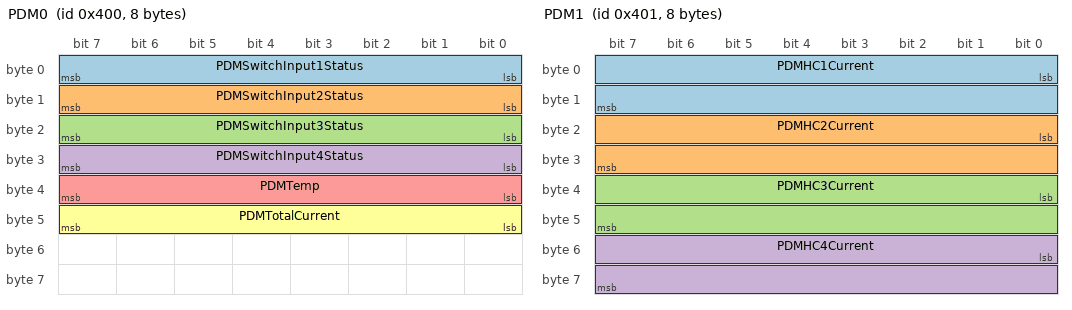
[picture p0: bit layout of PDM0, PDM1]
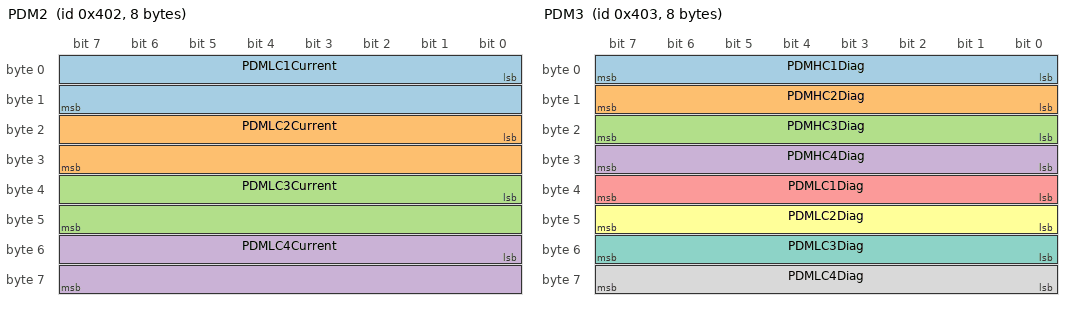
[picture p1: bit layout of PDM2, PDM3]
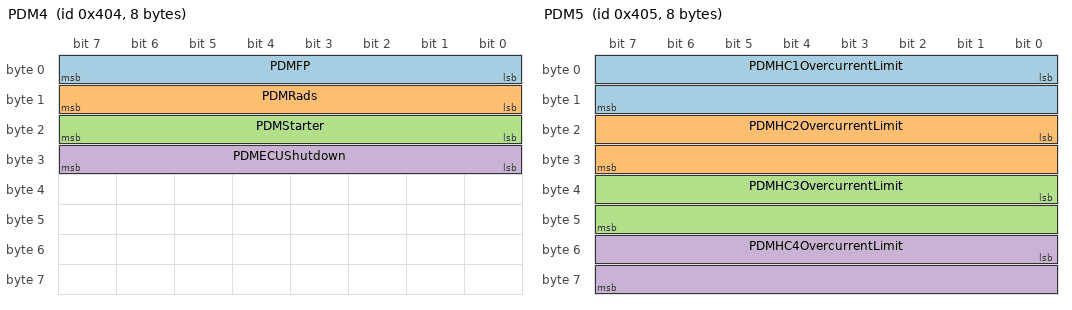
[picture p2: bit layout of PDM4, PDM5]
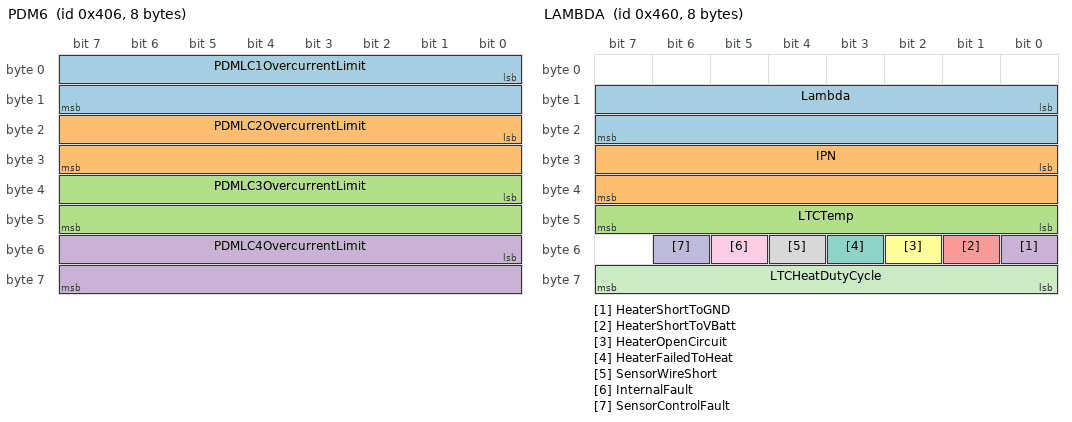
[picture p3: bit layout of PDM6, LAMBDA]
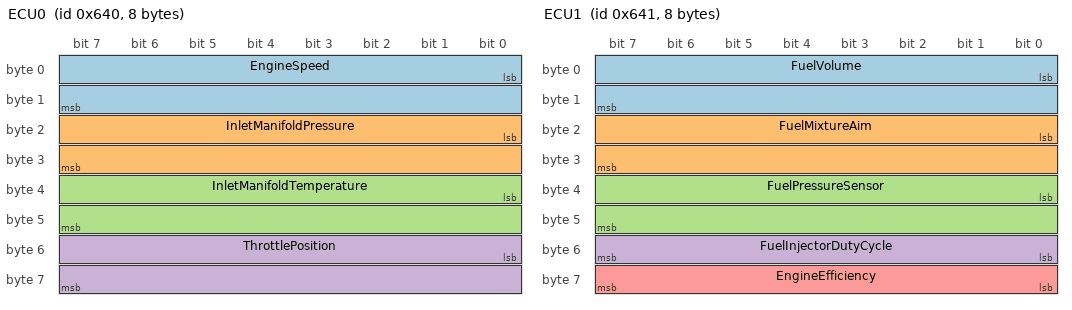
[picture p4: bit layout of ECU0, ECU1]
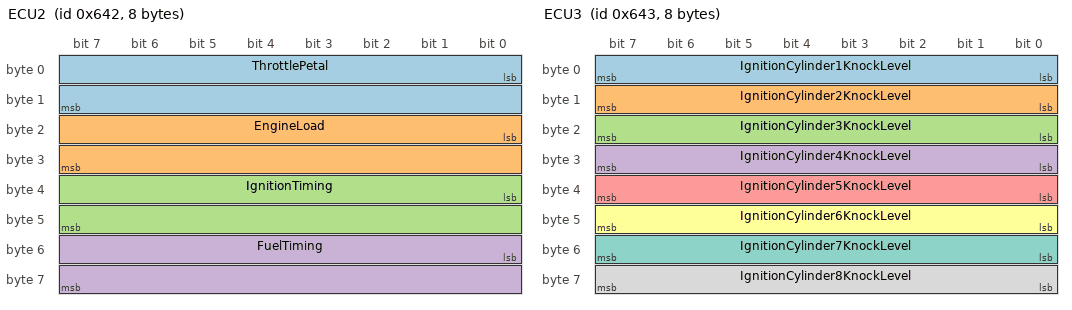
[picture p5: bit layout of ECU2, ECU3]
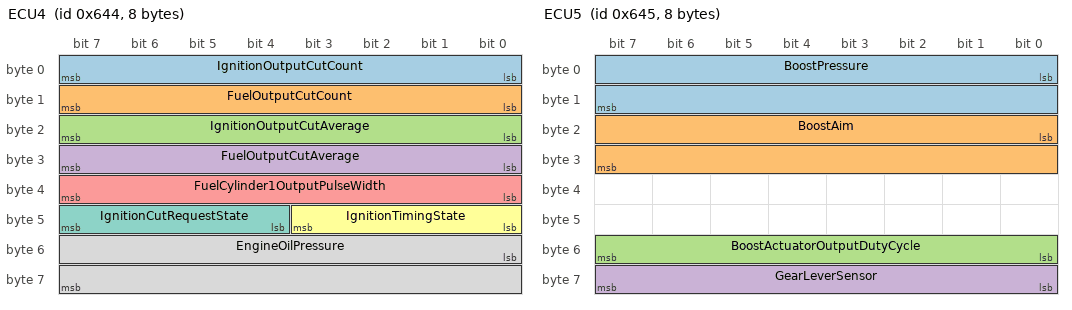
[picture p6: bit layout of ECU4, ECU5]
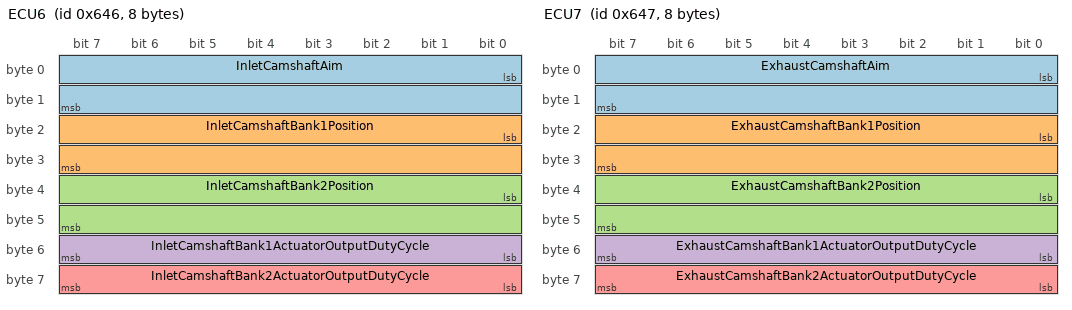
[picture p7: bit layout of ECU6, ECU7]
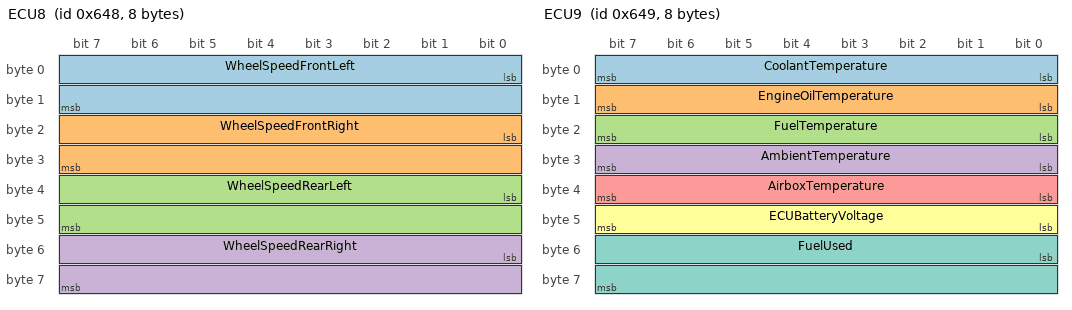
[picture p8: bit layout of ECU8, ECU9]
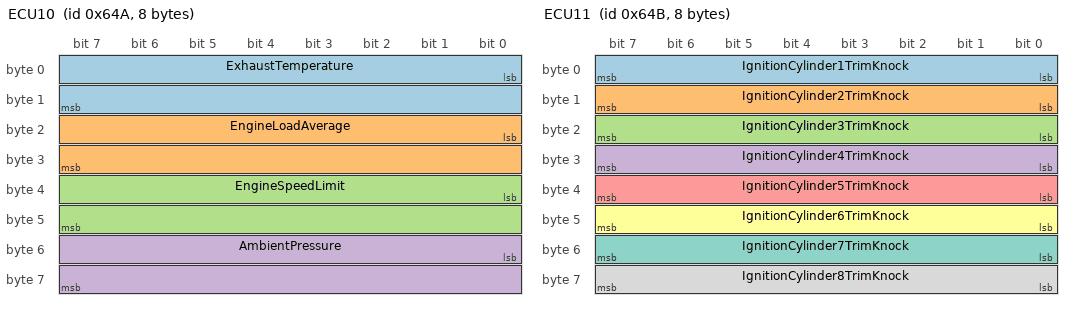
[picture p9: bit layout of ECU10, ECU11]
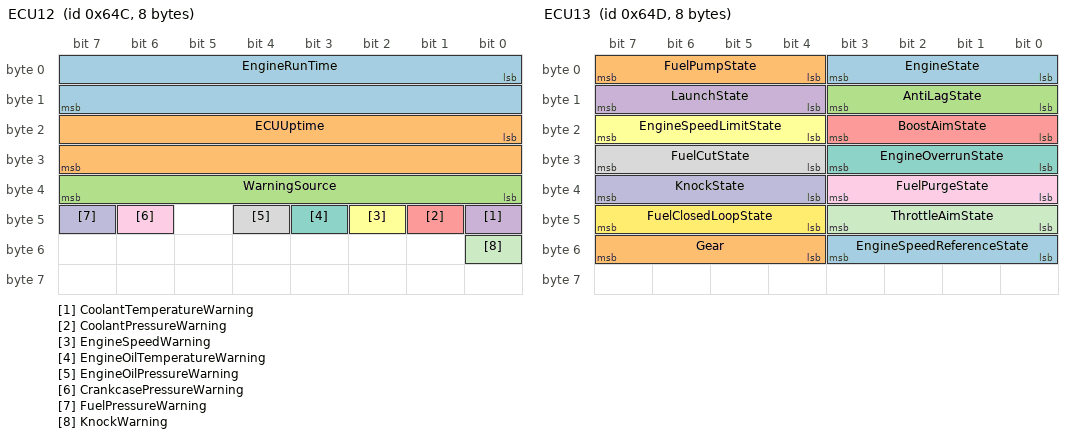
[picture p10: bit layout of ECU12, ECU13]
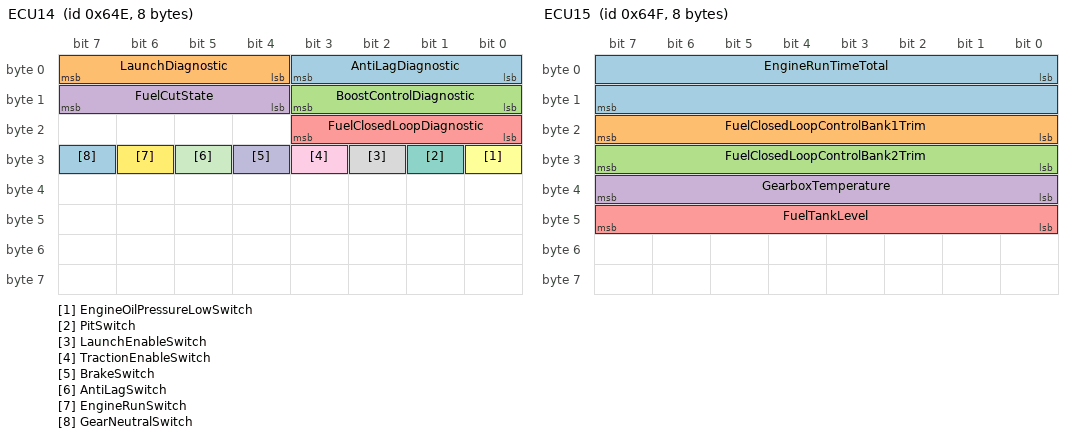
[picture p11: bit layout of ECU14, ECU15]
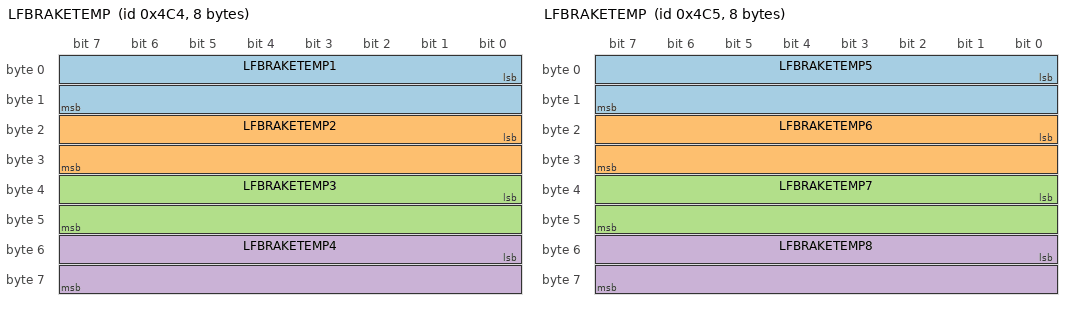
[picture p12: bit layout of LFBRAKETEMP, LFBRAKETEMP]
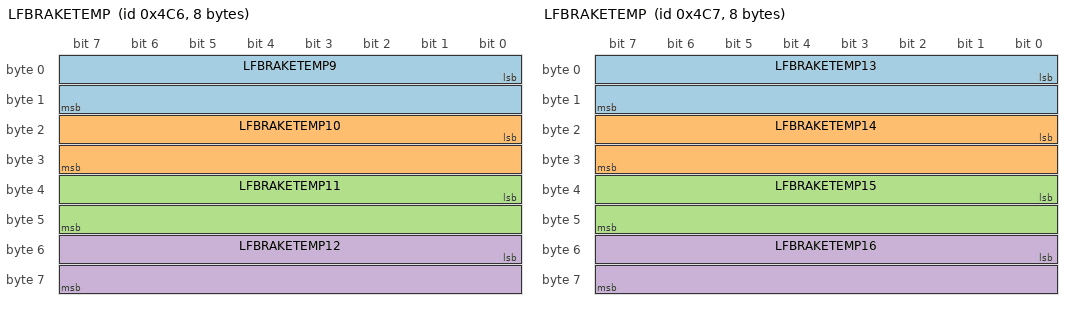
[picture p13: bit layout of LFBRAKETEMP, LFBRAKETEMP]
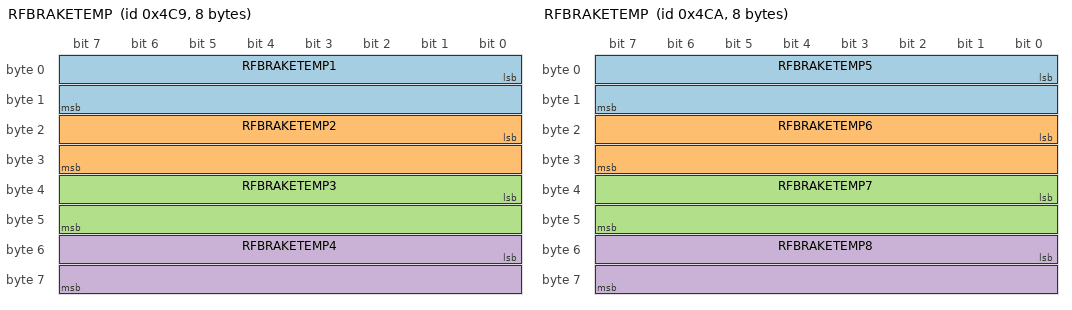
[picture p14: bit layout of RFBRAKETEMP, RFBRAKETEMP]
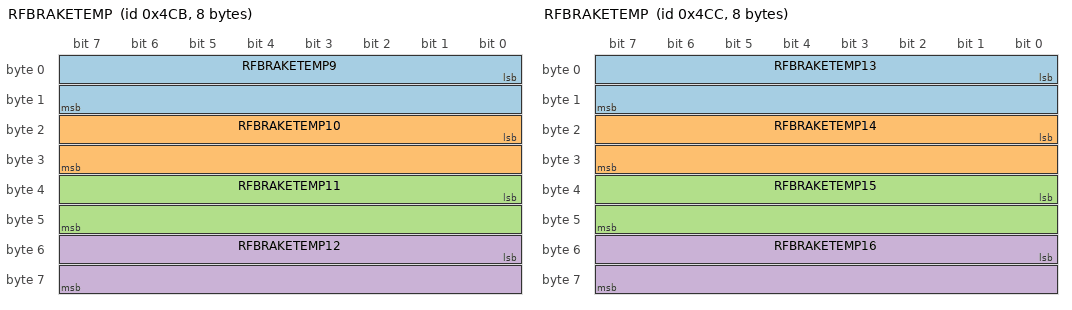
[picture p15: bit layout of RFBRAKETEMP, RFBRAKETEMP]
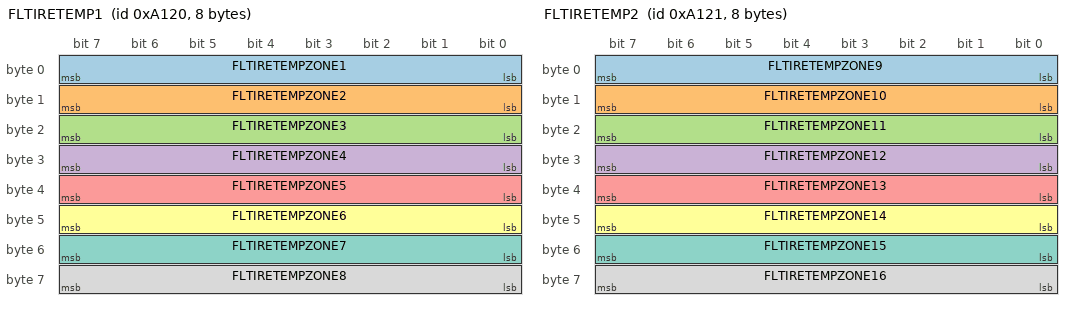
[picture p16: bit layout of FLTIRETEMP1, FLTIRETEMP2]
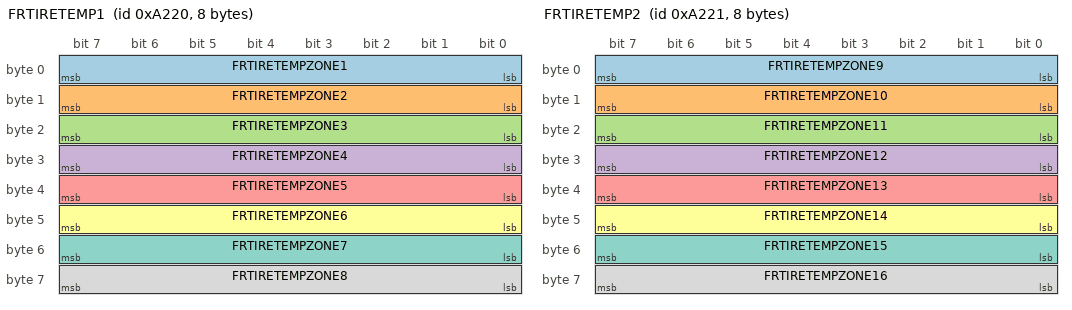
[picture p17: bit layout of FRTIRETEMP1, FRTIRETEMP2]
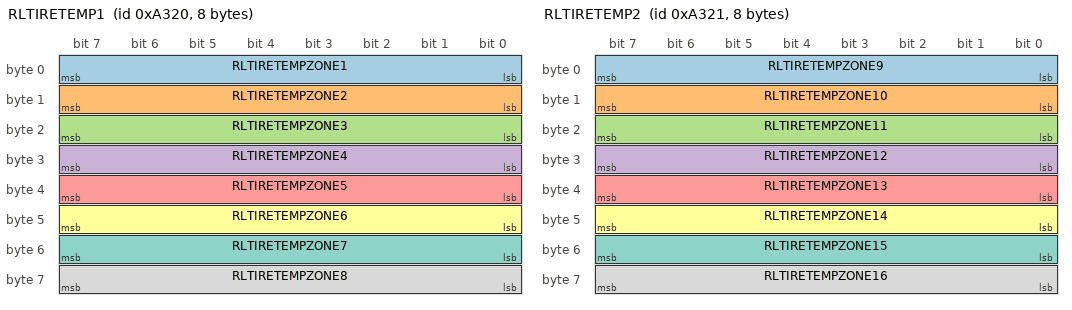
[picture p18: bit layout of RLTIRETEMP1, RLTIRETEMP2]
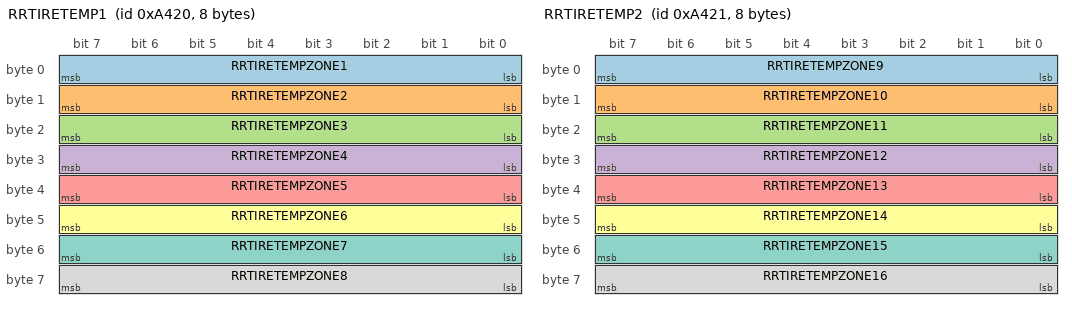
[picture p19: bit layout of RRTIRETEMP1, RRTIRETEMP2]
BO_ 0x400 PDM0: 8 Vector_XXX
    SG_ PDMSwitchInput1Status : 0|8@1+ (1,0) [0|65535] "flag"
    SG_ PDMSwitchInput2Status : 8|8@1+ (1,0) [0|65535] "flag"
    SG_ PDMSwitchInput3Status : 16|8@1+ (1,0) [0|65535] "flag"
    SG_ PDMSwitchInput4Status : 24|8@1+ (1,0) [0|65535] "flag"
    SG_ PDMTemp : 32|8@1- (1,0) [0|65535] "C"
    SG_ PDMTotalCurrent : 40|8@1+ (1,0) [0|65535] "A"

BO_ 0x401 PDM1: 8 Vector_XXX
    SG_ PDMHC1Current : 0|16@1+ (10,0) [0|65535] "A"
    SG_ PDMHC2Current : 16|16@1+ (10,0) [0|65535] "A"
    SG_ PDMHC3Current : 32|16@1+ (10,0) [0|65535] "A"
    SG_ PDMHC4Current : 48|16@1+ (10,0) [0|65535] "A"

BO_ 0x402 PDM2: 8 Vector_XXX
    SG_ PDMLC1Current : 0|16@1+ (10,0) [0|65535] "A"
    SG_ PDMLC2Current : 16|16@1+ (10,0) [0|65535] "A"
    SG_ PDMLC3Current : 32|16@1+ (10,0) [0|65535] "A"
    SG_ PDMLC4Current : 48|16@1+ (10,0) [0|65535] "A"

BO_ 0x403 PDM3: 8 Vector_XXX
    SG_ PDMHC1Diag : 0|8@1+ (1,0) [0|65535] "enumerated"
    SG_ PDMHC2Diag : 8|8@1+ (1,0) [0|65535] "enumerated"
    SG_ PDMHC3Diag : 16|8@1+ (1,0) [0|65535] "enumerated"
    SG_ PDMHC4Diag : 24|8@1+ (1,0) [0|65535] "enumerated"
    SG_ PDMLC1Diag : 32|8@1+ (1,0) [0|65535] "enumerated"
    SG_ PDMLC2Diag : 40|8@1+ (1,0) [0|65535] "enumerated"
    SG_ PDMLC3Diag : 48|8@1+ (1,0) [0|65535] "enumerated"
    SG_ PDMLC4Diag : 56|8@1+ (1,0) [0|65535] "enumerated"

BO_ 0x404 PDM4: 8 Vector_XXX
    SG_ PDMFP : 0|8@1+ (1,0) [0|65535] "enumerated"
    SG_ PDMRads : 8|8@1+ (1,0) [0|65535] "enumerated"
    SG_ PDMStarter : 16|8@1+ (1,0) [0|65535] "enumerated"
    SG_ PDMECUShutdown : 24|8@1+ (1,0) [0|65535] "enumerated"

BO_ 0x405 PDM5: 8 Vector_XXX
    SG_ PDMHC1OvercurrentLimit : 0|16@1+ (10,0) [0|65535] "A"
    SG_ PDMHC2OvercurrentLimit : 16|16@1+ (10,0) [0|65535] "A"
    SG_ PDMHC3OvercurrentLimit : 32|16@1+ (10,0) [0|65535] "A"
    SG_ PDMHC4OvercurrentLimit : 48|16@1+ (10,0) [0|65535] "A"

BO_ 0x406 PDM6: 8 Vector_XXX
    SG_ PDMLC1OvercurrentLimit : 0|16@1+ (10,0) [0|65535] "A"
    SG_ PDMLC2OvercurrentLimit : 16|16@1+ (10,0) [0|65535] "A"
    SG_ PDMLC3OvercurrentLimit : 32|16@1+ (10,0) [0|65535] "A"
    SG_ PDMLC4OvercurrentLimit : 48|16@1+ (10,0) [0|65535] "A"

BO_ 0x407 PDM7: 8 Vector_XXX
    SG_ CANaryRads : 0|8@1+ (10,0) [0|65535] "enumerated"

BO_ 0x460 LAMBDA: 8 Vector_XXX
    SG_ Lambda : 8|16@1+ (0.001,0) [0|65535] "lambda"
    SG_ IPN : 24|16@1+ (1,0) [0|65535] "uA"
    SG_ LTCTemp : 40|8@1+ (1,0) [0|65535] "C"
    SG_ HeaterShortToGND : 48|1@1+ (1,0) [0|65535] "flag"
    SG_ HeaterShortToVBatt : 49|1@1+ (1,0) [0|65535] "flag"
    SG_ HeaterOpenCircuit : 50|1@1+ (1,0) [0|65535] "flag"
    SG_ HeaterFailedToHeat : 51|1@1+ (1,0) [0|65535] "flag"
    SG_ SensorWireShort : 52|1@1+ (1,0) [0|65535] "flag"
    SG_ InternalFault : 53|1@1+ (1,0) [0|65535] "flag"
    SG_ SensorControlFault : 54|1@1+ (1,0) [0|65535] "flag"
    SG_ LTCHeatDutyCycle : 56|8@1+ (1,0) [0|65535] "%"

BO_ 0x640 ECU0: 8 Vector_XXX
    SG_ EngineSpeed : 0|16@1+ (1,0) [0|65535] "rpm"
    SG_ InletManifoldPressure : 16|16@1+ (0.1,0) [0|65535] "kPa"
    SG_ InletManifoldTemperature : 32|16@1- (0.1,0) [0|65535] "C"
    SG_ ThrottlePosition : 48|16@1+ (0.1,0) [0|65535] "%"

BO_ 0x641 ECU1: 8 Vector_XXX
    SG_ FuelVolume : 0|16@1+ (1,0) [0|65535] "uL"
    SG_ FuelMixtureAim : 16|16@1+ (0.01,0) [0|65535] "lambda"
    SG_ FuelPressureSensor : 32|16@1+ (0.1,0) [0|65535] "kPa"
    SG_ FuelInjectorDutyCycle : 48|8@1+ (1,0) [0|65535] "%"
    SG_ EngineEfficiency : 56|8@1+ (1,0) [0|65535] "%"

BO_ 0x642 ECU2: 8 Vector_XXX
    SG_ ThrottlePetal : 0|16@1+ (0.1,0) [0|65535] "%"
    SG_ EngineLoad : 16|16@1+ (1,0) [0|65535] "mg"
    SG_ IgnitionTiming : 32|16@1- (0.1,0) [0|65535] "degrees"
    SG_ FuelTiming : 48|16@1- (0.1,0) [0|65535] "degrees"

BO_ 0x643 ECU3: 8 Vector_XXX
    SG_ IgnitionCylinder1KnockLevel : 0|8@1+ (1,0) [0|65535] "%"
    SG_ IgnitionCylinder2KnockLevel : 8|8@1+ (1,0) [0|65535] "%"
    SG_ IgnitionCylinder3KnockLevel : 16|8@1+ (1,0) [0|65535] "%"
    SG_ IgnitionCylinder4KnockLevel : 24|8@1+ (1,0) [0|65535] "%"
    SG_ IgnitionCylinder5KnockLevel : 32|8@1+ (1,0) [0|65535] "%"
    SG_ IgnitionCylinder6KnockLevel : 40|8@1+ (1,0) [0|65535] "%"
    SG_ IgnitionCylinder7KnockLevel : 48|8@1+ (1,0) [0|65535] "%"
    SG_ IgnitionCylinder8KnockLevel : 56|8@1+ (1,0) [0|65535] "%"

BO_ 0x644 ECU4: 8 Vector_XXX
    SG_ IgnitionOutputCutCount : 0|8@1+ (1,0) [0|65535] "cut"
    SG_ FuelOutputCutCount : 8|8@1+ (1,0) [0|65535] "cut"
    SG_ IgnitionOutputCutAverage : 16|8@1+ (1,0) [0|65535] "%"
    SG_ FuelOutputCutAverage : 24|8@1+ (1,0) [0|65535] "%"
    SG_ FuelCylinder1OutputPulseWidth : 32|8@1+ (0.1,0) [0|65535] "mS"
    SG_ IgnitionTimingState : 40|4@1- (1,0) [0|65535] "enumerated"
    SG_ IgnitionCutRequestState : 44|4@1- (1,0) [0|65535] "enumerated"
    SG_ EngineOilPressure : 48|16@1+ (0.1,0) [0|65535] "kPa"

BO_ 0x645 ECU5: 8 Vector_XXX
    SG_ BoostPressure : 0|16@1- (0.1,0) [0|65535] "kPa"
    SG_ BoostAim : 16|16@1+ (0.1,0) [0|65535] "kPa"
    SG_ BoostActuatorOutputDutyCycle : 48|8@1+ (1,0) [0|65535] "%"
    SG_ GearLeverSensor : 56|8@1- (5,0) [0|65535] "N"

BO_ 0x646 ECU6: 8 Vector_XXX
    SG_ InletCamshaftAim : 0|16@1- (0.1,0) [0|65535] "degrees"
    SG_ InletCamshaftBank1Position : 16|16@1- (0.1,0) [0|65535] "degrees"
    SG_ InletCamshaftBank2Position : 32|16@1- (0.1,0) [0|65535] "degrees"
    SG_ InletCamshaftBank1ActuatorOutputDutyCycle : 48|8@1+ (1,0) [0|65535] "%"
    SG_ InletCamshaftBank2ActuatorOutputDutyCycle : 56|8@1+ (1,0) [0|65535] "%"

BO_ 0x647 ECU7: 8 Vector_XXX
    SG_ ExhaustCamshaftAim : 0|16@1- (0.1,0) [0|65535] "degrees"
    SG_ ExhaustCamshaftBank1Position : 16|16@1- (0.1,0) [0|65535] "degrees"
    SG_ ExhaustCamshaftBank2Position : 32|16@1- (0.1,0) [0|65535] "degrees"
    SG_ ExhaustCamshaftBank1ActuatorOutputDutyCycle : 48|8@1+ (1,0) [0|65535] "%"
    SG_ ExhaustCamshaftBank2ActuatorOutputDutyCycle : 56|8@1+ (1,0) [0|65535] "%"

BO_ 0x648 ECU8: 8 Vector_XXX
    SG_ WheelSpeedFrontLeft : 0|16@1+ (0.1,0) [0|65535] "km/h"
    SG_ WheelSpeedFrontRight : 16|16@1+ (0.1,0) [0|65535] "km/h"
    SG_ WheelSpeedRearLeft : 32|16@1+ (0.1,0) [0|65535] "km/h"
    SG_ WheelSpeedRearRight : 48|16@1+ (0.1,0) [0|65535] "km/h"

BO_ 0x649 ECU9: 8 Vector_XXX
    SG_ CoolantTemperature : 0|8@1+ (1,-40) [0|65535] "C"
    SG_ EngineOilTemperature : 8|8@1+ (1,-40) [0|65535] "C"
    SG_ FuelTemperature : 16|8@1+ (1,-40) [0|65535] "C"
    SG_ AmbientTemperature : 24|8@1+ (1,-40) [0|65535] "C"
    SG_ AirboxTemperature : 32|8@1+ (1,-40) [0|65535] "C"
    SG_ ECUBatteryVoltage : 40|8@1+ (0.1,0) [0|65535] "V"
    SG_ FuelUsed : 48|16@1+ (0.01,0) [0|65535] "L"

BO_ 0x64A ECU10: 8 Vector_XXX
    SG_ ExhaustTemperature : 0|16@1+ (0.1,0) [0|65535] "C"
    SG_ EngineLoadAverage : 16|16@1+ (0.1,0) [0|65535] "%"
    SG_ EngineSpeedLimit : 32|16@1+ (1,0) [0|65535] "rpm"
    SG_ AmbientPressure : 48|16@1+ (0.1,0) [0|65535] "kPa"

BO_ 0x64B ECU11: 8 Vector_XXX
    SG_ IgnitionCylinder1TrimKnock : 0|8@1+ (0.1,0) [0|65535] "degrees"
    SG_ IgnitionCylinder2TrimKnock : 8|8@1+ (0.1,0) [0|65535] "degrees"
    SG_ IgnitionCylinder3TrimKnock : 16|8@1+ (0.1,0) [0|65535] "degrees"
    SG_ IgnitionCylinder4TrimKnock : 24|8@1+ (0.1,0) [0|65535] "degrees"
    SG_ IgnitionCylinder5TrimKnock : 32|8@1+ (0.1,0) [0|65535] "degrees"
    SG_ IgnitionCylinder6TrimKnock : 40|8@1+ (0.1,0) [0|65535] "degrees"
    SG_ IgnitionCylinder7TrimKnock : 48|8@1+ (0.1,0) [0|65535] "degrees"
    SG_ IgnitionCylinder8TrimKnock : 56|8@1+ (0.1,0) [0|65535] "degrees"

BO_ 0x64C ECU12: 8 Vector_XXX
    SG_ EngineRunTime : 0|16@1+ (1,0) [0|65535] "s"
    SG_ ECUUptime : 16|16@1+ (1,0) [0|65535] "s"
    SG_ WarningSource : 32|8@1+ (1,0) [0|65535] "enumerated"
    SG_ CoolantTemperatureWarning : 40|1@1+ (1,0) [0|65535] "flag"
    SG_ CoolantPressureWarning : 41|1@1+ (1,0) [0|65535] "flag"
    SG_ EngineSpeedWarning : 42|1@1+ (1,0) [0|65535] "flag"
    SG_ EngineOilTemperatureWarning : 43|1@1+ (1,0) [0|65535] "flag"
    SG_ EngineOilPressureWarning : 44|1@1+ (1,0) [0|65535] "flag"
    SG_ CrankcasePressureWarning : 46|1@1+ (1,0) [0|65535] "flag"
    SG_ FuelPressureWarning : 47|1@1+ (1,0) [0|65535] "flag"
    SG_ KnockWarning : 48|1@1+ (1,0) [0|65535] "flag"

BO_ 0x64D ECU13: 8 Vector_XXX
    SG_ EngineState : 0|4@1+ (1,0) [0|65535] "enumerated"
    SG_ FuelPumpState : 4|4@1+ (1,0) [0|65535] "enumerated"
    SG_ AntiLagState : 8|4@1+ (1,0) [0|65535] "enumerated"
    SG_ LaunchState : 12|4@1+ (1,0) [0|65535] "enumerated"
    SG_ BoostAimState : 16|4@1+ (1,0) [0|65535] "enumerated"
    SG_ EngineSpeedLimitState : 20|4@1+ (1,0) [0|65535] "enumerated"
    SG_ EngineOverrunState : 24|4@1+ (1,0) [0|65535] "enumerated"
    SG_ FuelCutState : 28|4@1+ (1,0) [0|65535] "enumerated"
    SG_ FuelPurgeState : 32|4@1+ (1,0) [0|65535] "enumerated"
    SG_ KnockState : 36|4@1+ (1,0) [0|65535] "enumerated"
    SG_ ThrottleAimState : 40|4@1+ (1,0) [0|65535] "enumerated"
    SG_ FuelClosedLoopState : 44|4@1+ (1,0) [0|65535] "enumerated"
    SG_ EngineSpeedReferenceState : 48|4@1+ (1,0) [0|65535] "enumerated"
    SG_ Gear : 52|4@1- (1,0) [0|65535] "enumerated"

BO_ 0x64E ECU14: 8 Vector_XXX
    SG_ AntiLagDiagnostic : 0|4@1- (1,0) [0|65535] "enumerated"
    SG_ LaunchDiagnostic : 4|4@1- (1,0) [0|65535] "enumerated"
    SG_ BoostControlDiagnostic : 8|4@1- (1,0) [0|65535] "enumerated"
    SG_ FuelCutState : 12|4@1- (1,0) [0|65535] "enumerated"
    SG_ FuelClosedLoopDiagnostic : 16|4@1+ (1,0) [0|65535] "enumerated"
    SG_ EngineOilPressureLowSwitch : 24|1@1+ (1,0) [0|65535] "flag"
    SG_ PitSwitch : 25|1@1+ (1,0) [0|65535] "flag"
    SG_ LaunchEnableSwitch : 26|1@1+ (1,0) [0|65535] "flag"
    SG_ TractionEnableSwitch : 27|1@1+ (1,0) [0|65535] "flag"
    SG_ BrakeSwitch : 28|1@1+ (1,0) [0|65535] "flag"
    SG_ AntiLagSwitch : 29|1@1+ (1,0) [0|65535] "flag"
    SG_ EngineRunSwitch : 30|1@1+ (1,0) [0|65535] "flag"
    SG_ GearNeutralSwitch : 31|1@1+ (1,0) [0|65535] "flag"

BO_ 0x64F ECU15: 8 Vector_XXX
    SG_ EngineRunTimeTotal : 0|16@1+ (0.1,0) [0|65535] "hour"
    SG_ FuelClosedLoopControlBank1Trim : 16|8@1+ (0.5,0) [0|65535] "%"
    SG_ FuelClosedLoopControlBank2Trim : 24|8@1+ (0.5,0) [0|65535] "%"
    SG_ GearboxTemperature : 32|8@1+ (1,-40) [0|65535] "C"
    SG_ FuelTankLevel : 40|8@1+ (1,0) [0|65535] "l"

BO_ 0x4C4 LFBRAKETEMP: 8 Vector_XXX
    SG_ LFBRAKETEMP1 : 0|16@1+ (0.1,-100) [0|65535] "C"
    SG_ LFBRAKETEMP2 : 16|16@1+ (0.1,-100) [0|65535] "C"
    SG_ LFBRAKETEMP3 : 32|16@1+ (0.1,-100) [0|65535] "C"
    SG_ LFBRAKETEMP4 : 48|16@1+ (0.1,-100) [0|65535] "C"

BO_ 0x4C5 LFBRAKETEMP: 8 Vector_XXX
    SG_ LFBRAKETEMP5 : 0|16@1+ (0.1,-100) [0|65535] "C"
    SG_ LFBRAKETEMP6 : 16|16@1+ (0.1,-100) [0|65535] "C"
    SG_ LFBRAKETEMP7 : 32|16@1+ (0.1,-100) [0|65535] "C"
    SG_ LFBRAKETEMP8 : 48|16@1+ (0.1,-100) [0|65535] "C"

BO_ 0x4C6 LFBRAKETEMP: 8 Vector_XXX
    SG_ LFBRAKETEMP9 : 0|16@1+ (0.1,-100) [0|65535] "C"
    SG_ LFBRAKETEMP10 : 16|16@1+ (0.1,-100) [0|65535] "C"
    SG_ LFBRAKETEMP11 : 32|16@1+ (0.1,-100) [0|65535] "C"
    SG_ LFBRAKETEMP12 : 48|16@1+ (0.1,-100) [0|65535] "C"

BO_ 0x4C7 LFBRAKETEMP: 8 Vector_XXX
    SG_ LFBRAKETEMP13 : 0|16@1+ (0.1,-100) [0|65535] "C"
    SG_ LFBRAKETEMP14 : 16|16@1+ (0.1,-100) [0|65535] "C"
    SG_ LFBRAKETEMP15 : 32|16@1+ (0.1,-100) [0|65535] "C"
    SG_ LFBRAKETEMP16 : 48|16@1+ (0.1,-100) [0|65535] "C"

BO_ 0x4C8 LFBRAKETEMP: 8 Vector_XXX
    SG_ LFBRAKESENSORTEMP : 0|16@1+ (0.1,-100) [0|65535] "C"

BO_ 0x4C9 RFBRAKETEMP: 8 Vector_XXX
    SG_ RFBRAKETEMP1 : 0|16@1+ (0.1,-100) [0|65535] "C"
    SG_ RFBRAKETEMP2 : 16|16@1+ (0.1,-100) [0|65535] "C"
    SG_ RFBRAKETEMP3 : 32|16@1+ (0.1,-100) [0|65535] "C"
    SG_ RFBRAKETEMP4 : 48|16@1+ (0.1,-100) [0|65535] "C"

BO_ 0x4CA RFBRAKETEMP: 8 Vector_XXX
    SG_ RFBRAKETEMP5 : 0|16@1+ (0.1,-100) [0|65535] "C"
    SG_ RFBRAKETEMP6 : 16|16@1+ (0.1,-100) [0|65535] "C"
    SG_ RFBRAKETEMP7 : 32|16@1+ (0.1,-100) [0|65535] "C"
    SG_ RFBRAKETEMP8 : 48|16@1+ (0.1,-100) [0|65535] "C"

BO_ 0x4CB RFBRAKETEMP: 8 Vector_XXX
    SG_ RFBRAKETEMP9 : 0|16@1+ (0.1,-100) [0|65535] "C"
    SG_ RFBRAKETEMP10 : 16|16@1+ (0.1,-100) [0|65535] "C"
    SG_ RFBRAKETEMP11 : 32|16@1+ (0.1,-100) [0|65535] "C"
    SG_ RFBRAKETEMP12 : 48|16@1+ (0.1,-100) [0|65535] "C"

BO_ 0x4CC RFBRAKETEMP: 8 Vector_XXX
    SG_ RFBRAKETEMP13 : 0|16@1+ (0.1,-100) [0|65535] "C"
    SG_ RFBRAKETEMP14 : 16|16@1+ (0.1,-100) [0|65535] "C"
    SG_ RFBRAKETEMP15 : 32|16@1+ (0.1,-100) [0|65535] "C"
    SG_ RFBRAKETEMP16 : 48|16@1+ (0.1,-100) [0|65535] "C"

BO_ 0x4CD RFBRAKETEMP: 8 Vector_XXX
    SG_ RFBRAKESENSORTEMP : 0|16@1+ (0.1,-100) [0|65535] "C"

BO_ 0x4CE LRBRAKETEMP: 8 Vector_XXX
    SG_ LRBRAKETEMP1 : 0|16@1+ (0.1,-100) [0|65535] "C"
    SG_ LRBRAKETEMP2 : 16|16@1+ (0.1,-100) [0|65535] "C"
    SG_ LRBRAKETEMP3 : 32|16@1+ (0.1,-100) [0|65535] "C"
    SG_ LRBRAKETEMP4 : 48|16@1+ (0.1,-100) [0|65535] "C"

BO_ 0x4CF LRBRAKETEMP: 8 Vector_XXX
    SG_ LRBRAKETEMP5 : 0|16@1+ (0.1,-100) [0|65535] "C"
    SG_ LRBRAKETEMP6 : 16|16@1+ (0.1,-100) [0|65535] "C"
    SG_ LRBRAKETEMP7 : 32|16@1+ (0.1,-100) [0|65535] "C"
    SG_ LRBRAKETEMP8 : 48|16@1+ (0.1,-100) [0|65535] "C"

BO_ 0x4D0 LRBRAKETEMP: 8 Vector_XXX
    SG_ LRBRAKETEMP9 : 0|16@1+ (0.1,-100) [0|65535] "C"
    SG_ LRBRAKETEMP10 : 16|16@1+ (0.1,-100) [0|65535] "C"
    SG_ LRBRAKETEMP11 : 32|16@1+ (0.1,-100) [0|65535] "C"
    SG_ LRBRAKETEMP12 : 48|16@1+ (0.1,-100) [0|65535] "C"

BO_ 0x4D1 LRBRAKETEMP: 8 Vector_XXX
    SG_ LRBRAKETEMP13 : 0|16@1+ (0.1,-100) [0|65535] "C"
    SG_ LRBRAKETEMP14 : 16|16@1+ (0.1,-100) [0|65535] "C"
    SG_ LRBRAKETEMP15 : 32|16@1+ (0.1,-100) [0|65535] "C"
    SG_ LRBRAKETEMP16 : 48|16@1+ (0.1,-100) [0|65535] "C"

BO_ 0x4D2 LRBRAKETEMP: 8 Vector_XXX
    SG_ LRBRAKESENSORTEMP : 0|16@1+ (0.1,-100) [0|65535] "C"

BO_ 0x4D3 RRBRAKETEMP: 8 Vector_XXX
    SG_ RRBRAKETEMP1 : 0|16@1+ (0.1,-100) [0|65535] "C"
    SG_ RRBRAKETEMP2 : 16|16@1+ (0.1,-100) [0|65535] "C"
    SG_ RRBRAKETEMP3 : 32|16@1+ (0.1,-100) [0|65535] "C"
    SG_ RRBRAKETEMP4 : 48|16@1+ (0.1,-100) [0|65535] "C"

BO_ 0x4D4 RRBRAKETEMP: 8 Vector_XXX
    SG_ RRBRAKETEMP5 : 0|16@1+ (0.1,-100) [0|65535] "C"
    SG_ RRBRAKETEMP6 : 16|16@1+ (0.1,-100) [0|65535] "C"
    SG_ RRBRAKETEMP7 : 32|16@1+ (0.1,-100) [0|65535] "C"
    SG_ RRBRAKETEMP8 : 48|16@1+ (0.1,-100) [0|65535] "C"

BO_ 0x4D5 RRBRAKETEMP: 8 Vector_XXX
    SG_ RRBRAKETEMP9 : 0|16@1+ (0.1,-100) [0|65535] "C"
    SG_ RRBRAKETEMP10 : 16|16@1+ (0.1,-100) [0|65535] "C"
    SG_ RRBRAKETEMP11 : 32|16@1+ (0.1,-100) [0|65535] "C"
    SG_ RRBRAKETEMP12 : 48|16@1+ (0.1,-100) [0|65535] "C"

BO_ 0x4D6 RRBRAKETEMP: 8 Vector_XXX
    SG_ RRBRAKETEMP13 : 0|16@1+ (0.1,-100) [0|65535] "C"
    SG_ RRBRAKETEMP14 : 16|16@1+ (0.1,-100) [0|65535] "C"
    SG_ RRBRAKETEMP15 : 32|16@1+ (0.1,-100) [0|65535] "C"
    SG_ RRBRAKETEMP16 : 48|16@1+ (0.1,-100) [0|65535] "C"

BO_ 0x4D7 RRBRAKETEMP: 8 Vector_XXX
    SG_ RRBRAKESENSORTEMP : 0|16@1+ (0.1,-100) [0|65535] "C"

BO_ 0xA120 FLTIRETEMP1: 8 Vector_XXX
    SG_ FLTIRETEMPZONE1 : 0|8@1+ (0.5,0) [0|65535] "C"
    SG_ FLTIRETEMPZONE2 : 8|8@1+ (0.5,0) [0|65535] "C"
    SG_ FLTIRETEMPZONE3 : 16|8@1+ (0.5,0) [0|65535] "C"
    SG_ FLTIRETEMPZONE4 : 24|8@1+ (0.5,0) [0|65535] "C"
    SG_ FLTIRETEMPZONE5 : 32|8@1+ (0.5,0) [0|65535] "C"
    SG_ FLTIRETEMPZONE6 : 40|8@1+ (0.5,0) [0|65535] "C"
    SG_ FLTIRETEMPZONE7 : 48|8@1+ (0.5,0) [0|65535] "C"
    SG_ FLTIRETEMPZONE8 : 56|8@1+ (0.5,0) [0|65535] "C"

BO_ 0xA121 FLTIRETEMP2: 8 Vector_XXX
    SG_ FLTIRETEMPZONE9 : 0|8@1+ (0.5,0) [0|65535] "C"
    SG_ FLTIRETEMPZONE10 : 8|8@1+ (0.5,0) [0|65535] "C"
    SG_ FLTIRETEMPZONE11 : 16|8@1+ (0.5,0) [0|65535] "C"
    SG_ FLTIRETEMPZONE12 : 24|8@1+ (0.5,0) [0|65535] "C"
    SG_ FLTIRETEMPZONE13 : 32|8@1+ (0.5,0) [0|65535] "C"
    SG_ FLTIRETEMPZONE14 : 40|8@1+ (0.5,0) [0|65535] "C"
    SG_ FLTIRETEMPZONE15 : 48|8@1+ (0.5,0) [0|65535] "C"
    SG_ FLTIRETEMPZONE16 : 56|8@1+ (0.5,0) [0|65535] "C"

BO_ 0xA220 FRTIRETEMP1: 8 Vector_XXX
    SG_ FRTIRETEMPZONE1 : 0|8@1+ (0.5,0) [0|65535] "C"
    SG_ FRTIRETEMPZONE2 : 8|8@1+ (0.5,0) [0|65535] "C"
    SG_ FRTIRETEMPZONE3 : 16|8@1+ (0.5,0) [0|65535] "C"
    SG_ FRTIRETEMPZONE4 : 24|8@1+ (0.5,0) [0|65535] "C"
    SG_ FRTIRETEMPZONE5 : 32|8@1+ (0.5,0) [0|65535] "C"
    SG_ FRTIRETEMPZONE6 : 40|8@1+ (0.5,0) [0|65535] "C"
    SG_ FRTIRETEMPZONE7 : 48|8@1+ (0.5,0) [0|65535] "C"
    SG_ FRTIRETEMPZONE8 : 56|8@1+ (0.5,0) [0|65535] "C"

BO_ 0xA221 FRTIRETEMP2: 8 Vector_XXX
    SG_ FRTIRETEMPZONE9 : 0|8@1+ (0.5,0) [0|65535] "C"
    SG_ FRTIRETEMPZONE10 : 8|8@1+ (0.5,0) [0|65535] "C"
    SG_ FRTIRETEMPZONE11 : 16|8@1+ (0.5,0) [0|65535] "C"
    SG_ FRTIRETEMPZONE12 : 24|8@1+ (0.5,0) [0|65535] "C"
    SG_ FRTIRETEMPZONE13 : 32|8@1+ (0.5,0) [0|65535] "C"
    SG_ FRTIRETEMPZONE14 : 40|8@1+ (0.5,0) [0|65535] "C"
    SG_ FRTIRETEMPZONE15 : 48|8@1+ (0.5,0) [0|65535] "C"
    SG_ FRTIRETEMPZONE16 : 56|8@1+ (0.5,0) [0|65535] "C"

BO_ 0xA320 RLTIRETEMP1: 8 Vector_XXX
    SG_ RLTIRETEMPZONE1 : 0|8@1+ (0.5,0) [0|65535] "C"
    SG_ RLTIRETEMPZONE2 : 8|8@1+ (0.5,0) [0|65535] "C"
    SG_ RLTIRETEMPZONE3 : 16|8@1+ (0.5,0) [0|65535] "C"
    SG_ RLTIRETEMPZONE4 : 24|8@1+ (0.5,0) [0|65535] "C"
    SG_ RLTIRETEMPZONE5 : 32|8@1+ (0.5,0) [0|65535] "C"
    SG_ RLTIRETEMPZONE6 : 40|8@1+ (0.5,0) [0|65535] "C"
    SG_ RLTIRETEMPZONE7 : 48|8@1+ (0.5,0) [0|65535] "C"
    SG_ RLTIRETEMPZONE8 : 56|8@1+ (0.5,0) [0|65535] "C"

BO_ 0xA321 RLTIRETEMP2: 8 Vector_XXX
    SG_ RLTIRETEMPZONE9 : 0|8@1+ (0.5,0) [0|65535] "C"
    SG_ RLTIRETEMPZONE10 : 8|8@1+ (0.5,0) [0|65535] "C"
    SG_ RLTIRETEMPZONE11 : 16|8@1+ (0.5,0) [0|65535] "C"
    SG_ RLTIRETEMPZONE12 : 24|8@1+ (0.5,0) [0|65535] "C"
    SG_ RLTIRETEMPZONE13 : 32|8@1+ (0.5,0) [0|65535] "C"
    SG_ RLTIRETEMPZONE14 : 40|8@1+ (0.5,0) [0|65535] "C"
    SG_ RLTIRETEMPZONE15 : 48|8@1+ (0.5,0) [0|65535] "C"
    SG_ RLTIRETEMPZONE16 : 56|8@1+ (0.5,0) [0|65535] "C"

BO_ 0xA420 RRTIRETEMP1: 8 Vector_XXX
    SG_ RRTIRETEMPZONE1 : 0|8@1+ (0.5,0) [0|65535] "C"
    SG_ RRTIRETEMPZONE2 : 8|8@1+ (0.5,0) [0|65535] "C"
    SG_ RRTIRETEMPZONE3 : 16|8@1+ (0.5,0) [0|65535] "C"
    SG_ RRTIRETEMPZONE4 : 24|8@1+ (0.5,0) [0|65535] "C"
    SG_ RRTIRETEMPZONE5 : 32|8@1+ (0.5,0) [0|65535] "C"
    SG_ RRTIRETEMPZONE6 : 40|8@1+ (0.5,0) [0|65535] "C"
    SG_ RRTIRETEMPZONE7 : 48|8@1+ (0.5,0) [0|65535] "C"
    SG_ RRTIRETEMPZONE8 : 56|8@1+ (0.5,0) [0|65535] "C"

BO_ 0xA421 RRTIRETEMP2: 8 Vector_XXX
    SG_ RRTIRETEMPZONE9 : 0|8@1+ (0.5,0) [0|65535] "C"
    SG_ RRTIRETEMPZONE10 : 8|8@1+ (0.5,0) [0|65535] "C"
    SG_ RRTIRETEMPZONE11 : 16|8@1+ (0.5,0) [0|65535] "C"
    SG_ RRTIRETEMPZONE12 : 24|8@1+ (0.5,0) [0|65535] "C"
    SG_ RRTIRETEMPZONE13 : 32|8@1+ (0.5,0) [0|65535] "C"
    SG_ RRTIRETEMPZONE14 : 40|8@1+ (0.5,0) [0|65535] "C"
    SG_ RRTIRETEMPZONE15 : 48|8@1+ (0.5,0) [0|65535] "C"
    SG_ RRTIRETEMPZONE16 : 56|8@1+ (0.5,0) [0|65535] "C"

BO_ 0x001 ANALOG1: 8 Vector_XXX
    SG_ STEERINGANGLE : 32|16@1+ (0.0488281248,-100) [0|65535] "mm"
    SG_ SHIFTPRESSURE : 48|16@1+ (0.00122070312,-0.5) [0|65535] "V"

BO_ 0x002 ANALOG2: 8 Vector_XXX
    SG_ SHOCKRR : 0|16@1+ (0.0183105468,75) [0|65535] "mm"
    SG_ SHOCKRL : 16|16@1+ (0.0183105468,75) [0|65535] "mm"
    SG_ SHOCKFR : 32|16@1+ (0.0183105468,75) [0|65535] "mm"
    SG_ SHOCKFL : 48|16@1+ (0.0183105468,75) [0|65535] "mm"

BO_ 0x408 RANDOM1: 8 Vector_XXX
    SG_ nothing1 : 0|8@1+ (1,0) [0|65535] "x"

BO_ 0x410 RANDOM2: 8 Vector_XXX
    SG_ nothing2 : 0|8@1+ (1,0) [0|65535] "x"

BO_ 0x630 RANDOM3: 8 Vector_XXX
    SG_ nothing3 : 0|8@1+ (1,0) [0|65535] "x"

BO_ 0x631 RANDOM4: 8 Vector_XXX
    SG_ nothing4 : 0|8@1+ (1,0) [0|65535] "x"

BO_ 0x632 RANDOM5: 8 Vector_XXX
    SG_ nothing5 : 0|8@1+ (1,0) [0|65535] "x"

BO_ 0x633 RANDOM6: 8 Vector_XXX
    SG_ nothing6 : 0|8@1+ (1,0) [0|65535] "x"

BO_ 0x634 RANDOM7: 8 Vector_XXX
    SG_ nothing7 : 0|8@1+ (1,0) [0|65535] "x"

BO_ 0x635 RANDOM8: 8 Vector_XXX
    SG_ nothing8 : 0|8@1+ (1,0) [0|65535] "x"

BO_ 0x636 RANDOM9: 8 Vector_XXX
    SG_ nothing9 : 0|8@1+ (1,0) [0|65535] "x"

BO_ 0xA100 FLTIRETEMPANNOUNCEMENT: 8 Vector_XXX
    SG_ nothing10 : 0|8@1+ (1,0) [0|65535] "x"

BO_ 0xA102 FLTIRETEMPSTATS: 8 Vector_XXX
    SG_ nothing11 : 0|8@1+ (1,0) [0|65535] "x"

BO_ 0xA103 FLTIRETEMPCONFIG1: 8 Vector_XXX
    SG_ nothing12 : 0|8@1+ (1,0) [0|65535] "x"

BO_ 0xA104 FLTIRETEMPCONFIG2: 8 Vector_XXX
    SG_ nothing13 : 0|8@1+ (1,0) [0|65535] "x"

BO_ 0xA200 FRTIRETEMPANNOUNCEMENT: 8 Vector_XXX
    SG_ nothing14 : 0|8@1+ (1,0) [0|65535] "x"

BO_ 0xA202 FRTIRETEMPSTATS: 8 Vector_XXX
    SG_ nothing15 : 0|8@1+ (1,0) [0|65535] "x"

BO_ 0xA203 FRTIRETEMPCONFIG1: 8 Vector_XXX
    SG_ nothing16 : 0|8@1+ (1,0) [0|65535] "x"

BO_ 0xA204 FRTIRETEMPCONFIG2: 8 Vector_XXX
    SG_ nothing17 : 0|8@1+ (1,0) [0|65535] "x"

BO_ 0xA300 RLTIRETEMPANNOUNCEMENT: 8 Vector_XXX
    SG_ nothing18 : 0|8@1+ (1,0) [0|65535] "x"

BO_ 0xA302 RLTIRETEMPSTATS: 8 Vector_XXX
    SG_ nothing19 : 0|8@1+ (1,0) [0|65535] "x"

BO_ 0xA303 RLTIRETEMPCONFIG1: 8 Vector_XXX
    SG_ nothing20 : 0|8@1+ (1,0) [0|65535] "x"

BO_ 0xA304 RLTIRETEMPCONFIG2: 8 Vector_XXX
    SG_ nothing21 : 0|8@1+ (1,0) [0|65535] "x"

BO_ 0xA400 RRTIRETEMPANNOUNCEMENT: 8 Vector_XXX
    SG_ nothing22 : 0|8@1+ (1,0) [0|65535] "x"

BO_ 0xA402 RRTIRETEMPSTATS: 8 Vector_XXX
    SG_ nothing23 : 0|8@1+ (1,0) [0|65535] "x"

BO_ 0xA403 RRTIRETEMPCONFIG1: 8 Vector_XXX
    SG_ nothing24 : 0|8@1+ (1,0) [0|65535] "x"

BO_ 0xA404 RRTIRETEMPCONFIG2: 8 Vector_XXX
    SG_ nothing25 : 0|8@1+ (1,0) [0|65535] "x"
